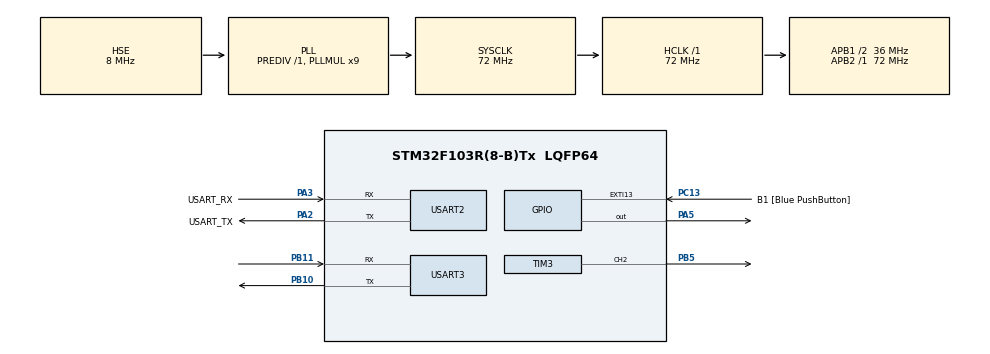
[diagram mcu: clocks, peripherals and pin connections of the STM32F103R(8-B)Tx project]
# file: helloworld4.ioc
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Mcu.Family=STM32F1
Mcu.Name=STM32F103R(8-B)Tx
Mcu.Package=LQFP64
NVIC.EXTI15_10_IRQn=true\:0\:0\:false\:false\:true\:true\:true\:true
NVIC.PriorityGroup=NVIC_PRIORITYGROUP_4
PA13.GPIO_Label=TMS
PA13.Mode=Serial_Wire
PA13.Signal=SYS_JTMS-SWDIO
PA14.GPIO_Label=TCK
PA14.Mode=Serial_Wire
PA14.Signal=SYS_JTCK-SWCLK
PA2.GPIO_Label=USART_TX
PA2.GPIO_Mode=GPIO_MODE_AF_PP
PA2.GPIO_PuPd=GPIO_NOPULL
PA2.GPIO_Speed=GPIO_SPEED_FREQ_LOW
PA2.Mode=Asynchronous
PA2.Signal=USART2_TX
PA3.GPIO_Label=USART_RX
PA3.GPIO_Mode=GPIO_MODE_AF_PP
PA3.GPIO_PuPd=GPIO_NOPULL
PA3.GPIO_Speed=GPIO_SPEED_FREQ_LOW
PA3.Mode=Asynchronous
PA3.Signal=USART2_RX
PA5.Signal=GPIO_Output
PB10.Mode=Asynchronous
PB10.Signal=USART3_TX
PB11.Mode=Asynchronous
PB11.Signal=USART3_RX
PB3.GPIO_Label=SWO
PB3.Signal=SYS_JTDO-TRACESWO
PB5.Signal=S_TIM3_CH2
PC13-TAMPER-RTC.GPIO_Label=B1 [Blue PushButton]
PC13-TAMPER-RTC.GPIO_PuPd=GPIO_NOPULL
PC13-TAMPER-RTC.Signal=GPXTI13
PC14-OSC32_IN.Mode=LSE-External-Oscillator
PC14-OSC32_IN.Signal=RCC_OSC32_IN
PC15-OSC32_OUT.Mode=LSE-External-Oscillator
PC15-OSC32_OUT.Signal=RCC_OSC32_OUT
PD0-OSC_IN.Mode=HSE-External-Clock-Source
PD0-OSC_IN.Signal=RCC_OSC_IN
PD1-OSC_OUT.Mode=HSE-External-Clock-Source
PD1-OSC_OUT.Signal=RCC_OSC_OUT
ProjectManager.HeapSize=0x200
ProjectManager.StackSize=0x400
ProjectManager.TargetToolchain=STM32CubeIDE
RCC.AHBFreq_Value=72000000
RCC.APB1CLKDivider=RCC_HCLK_DIV2
RCC.APB1Freq_Value=36000000
RCC.APB1TimFreq_Value=72000000
RCC.APB2Freq_Value=72000000
RCC.APB2TimFreq_Value=72000000
RCC.HCLKFreq_Value=72000000
RCC.PLLMUL=RCC_PLL_MUL9
RCC.PLLSourceVirtual=RCC_PLLSOURCE_HSE
RCC.RTCClockSelection=RCC_RTCCLKSOURCE_LSE
RCC.SYSCLKFreq_VALUE=72000000
RCC.SYSCLKSource=RCC_SYSCLKSOURCE_PLLCLK
RCC.USBFreq_Value=72000000
SH.S_TIM3_CH2.0=TIM3_CH2,PWM Generation2 CH2
TIM3.Channel-PWM\ Generation2\ CH2=TIM_CHANNEL_2
TIM3.Period=19999
TIM3.Prescaler=72
USART2.VirtualMode=VM_ASYNC
USART3.VirtualMode=VM_ASYNC
VP_TIM3_VS_ClockSourceINT.Mode=Internal
board=NUCLEO-F103RB

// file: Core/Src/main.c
/* USER CODE BEGIN Header */
/**
  ******************************************************************************
  * @file           : main.c
  * @brief          : Main program body
  ******************************************************************************
  * @attention
  *
  * Copyright (c) 2026 STMicroelectronics.
  * All rights reserved.
  *
  * This software is licensed under terms that can be found in the LICENSE file
  * in the root directory of this software component.
  * If no LICENSE file comes with this software, it is provided AS-IS.
  *
  ******************************************************************************
  */
/* USER CODE END Header */
#include "main.h"

TIM_HandleTypeDef htim3;

UART_HandleTypeDef huart2;
UART_HandleTypeDef huart3;

void SystemClock_Config(void);
static void MX_GPIO_Init(void);
static void MX_USART2_UART_Init(void);
static void MX_USART3_UART_Init(void);
static void MX_TIM3_Init(void);

int main(void)
{

  /* MCU Configuration--------------------------------------------------------*/

  /* Reset of all peripherals, Initializes the Flash interface and the Systick. */
  HAL_Init();

  /* Configure the system clock */
  SystemClock_Config();

  /* Initialize all configured peripherals */
  MX_GPIO_Init();
  MX_USART2_UART_Init();
  MX_USART3_UART_Init();
  MX_TIM3_Init();
  /* USER CODE BEGIN 2 */

//  int num = 0;
  //내가 입력할 문자열이 초과되지 않을만큼 넉넉하게 ~
  char text[100] = {0};
  char text2[100] = {0};
  /* USER CODE END 2 */

  /* Infinite loop */
  /* USER CODE BEGIN WHILE */
  while (1)
  {
	  //text라는 배열에 내가 지정한 문자열을 포멧을 이용해서 입력하겠다!
//	  sprintf(text,"num = %d",num);
//	  //1초간격으로 증가되는 null값을 C#에 전송한다
//	  HAL_UART_Transmit(&huart2, text, strlen(text), 100);
//	  num++;
//	  HAL_Delay(1000);

//	  //HAL_GetTick() : STM내부의 타이머 카운터값을 반환
//	  //STM32가 켜지면 0부터 출발해서 1밀리초당 1씩 증가
//	  sprintf(text, "GetTick = %d\n", HAL_GetTick());
//	  HAL_UART_Transmit(&huart2, text, strlen(text), 100);
//	  HAL_Delay(1000);

	  //example3 : C#이 보낸 고정길이의 데이터를 수신해라!
//	  if(HAL_UART_Receive(&huart2, text, 5, 500) == HAL_OK) {
//		  //송신용 text2 데이터 만들기
////		  sprintf(text2,"stm32 = %s\n",text);
////		  HAL_UART_Transmit(&huart2, text2, strlen(text2), 100);
//
//		  //현재 수신데이터는 text에 있는 상태이다.
//		  if(strcmp(text, "12345") == 0) {
//			  //일치
//			  HAL_UART_Transmit(&huart2, "LED_ON!\n", 8, 100);
//			  //PA5에 연결된 LED를 ON한다.
//			  HAL_GPIO_WritePin(GPIOA,GPIO_PIN_5, 1);
//		  } else if (strcmp(text, "67890") == 0) {
//			  //일치
//			  HAL_UART_Transmit(&huart2, "LED_OFF!\n", 9, 100);
//		  	  HAL_GPIO_WritePin(GPIOA,GPIO_PIN_5, 0);
//		  }
//	  }

	  //example4 C#이 길이가 가변적인 데이터를 보내는데 종료문자는 \n이다!
	  //C#에서 송신한 데이터가 있다면 1개씩 읽어서 수신버퍼에 카피한다
	  //그리고 종료문자가 감지되면 입력도니 문자열 한세트를 반환한다
//	  char recv = 0;
//	  int pos = 0;
//	  while(HAL_UART_Receive(&huart2, &recv, 1, 500) == HAL_OK) {
//		  text[pos] = recv;
//		  pos++;
//
//		  if(recv == '\n') {
//			 //종료조건
//			 text[pos] = '\0'; //널문자
//			 sprintf(text2,"stm32 = %s",text);
//			 HAL_UART_Transmit(&huart2, text2, strlen(text2), 100);
//
//			 //led on 수신시 PA5 ON
//			 //led off 수신시 PA5 OFF
//			 if(strcmp(text, "led on\n") == 0) {
//				 HAL_GPIO_WritePin(GPIOA,GPIO_PIN_5, 1);
//			 } else if(strcmp(text, "led off\n") == 0) {
//				 HAL_GPIO_WritePin(GPIOA,GPIO_PIN_5, 0);
//			 }
//			 break;
//		  }
//	  }

	  //example5 5초 간격으로 STM32가 C#쪽으로 hello world! 출력한다
	  HAL_UART_Transmit(&huart2, "Hello World!\n", 13, 100);
	  //STM32 메인루프는 HAL_Delay를 만나면 몯ㄴ 기능이 중지된다.
	  HAL_Delay(5000);
	  //버튼을 누르면 LED가 토글되도록 하려면 어떻게 해야겠는가?
	  //GPIO EXTI(외부 인터럽트)

    /* USER CODE END WHILE */

  }
}

void SystemClock_Config(void)
{
  RCC_OscInitTypeDef RCC_OscInitStruct = {0};
  RCC_ClkInitTypeDef RCC_ClkInitStruct = {0};

  /** Initializes the RCC Oscillators according to the specified parameters
  * in the RCC_OscInitTypeDef structure.
  */
  RCC_OscInitStruct.OscillatorType = RCC_OSCILLATORTYPE_HSE;
  RCC_OscInitStruct.HSEState = RCC_HSE_BYPASS;
  RCC_OscInitStruct.HSEPredivValue = RCC_HSE_PREDIV_DIV1;
  RCC_OscInitStruct.HSIState = RCC_HSI_ON;
  RCC_OscInitStruct.PLL.PLLState = RCC_PLL_ON;
  RCC_OscInitStruct.PLL.PLLSource = RCC_PLLSOURCE_HSE;
  RCC_OscInitStruct.PLL.PLLMUL = RCC_PLL_MUL9;
  if (HAL_RCC_OscConfig(&RCC_OscInitStruct) != HAL_OK)
  {
    Error_Handler();
  }

  /** Initializes the CPU, AHB and APB buses clocks
  */
  RCC_ClkInitStruct.ClockType = RCC_CLOCKTYPE_HCLK|RCC_CLOCKTYPE_SYSCLK
                              |RCC_CLOCKTYPE_PCLK1|RCC_CLOCKTYPE_PCLK2;
  RCC_ClkInitStruct.SYSCLKSource = RCC_SYSCLKSOURCE_PLLCLK;
  RCC_ClkInitStruct.AHBCLKDivider = RCC_SYSCLK_DIV1;
  RCC_ClkInitStruct.APB1CLKDivider = RCC_HCLK_DIV2;
  RCC_ClkInitStruct.APB2CLKDivider = RCC_HCLK_DIV1;

  if (HAL_RCC_ClockConfig(&RCC_ClkInitStruct, FLASH_LATENCY_2) != HAL_OK)
  {
    Error_Handler();
  }
}

static void MX_TIM3_Init(void)
{

  TIM_ClockConfigTypeDef sClockSourceConfig = {0};
  TIM_MasterConfigTypeDef sMasterConfig = {0};
  TIM_OC_InitTypeDef sConfigOC = {0};

  htim3.Instance = TIM3;
  htim3.Init.Prescaler = 72;
  htim3.Init.CounterMode = TIM_COUNTERMODE_UP;
  htim3.Init.Period = 19999;
  htim3.Init.ClockDivision = TIM_CLOCKDIVISION_DIV1;
  htim3.Init.AutoReloadPreload = TIM_AUTORELOAD_PRELOAD_DISABLE;
  if (HAL_TIM_Base_Init(&htim3) != HAL_OK)
  {
    Error_Handler();
  }
  sClockSourceConfig.ClockSource = TIM_CLOCKSOURCE_INTERNAL;
  if (HAL_TIM_ConfigClockSource(&htim3, &sClockSourceConfig) != HAL_OK)
  {
    Error_Handler();
  }
  if (HAL_TIM_PWM_Init(&htim3) != HAL_OK)
  {
    Error_Handler();
  }
  sMasterConfig.MasterOutputTrigger = TIM_TRGO_RESET;
  sMasterConfig.MasterSlaveMode = TIM_MASTERSLAVEMODE_DISABLE;
  if (HAL_TIMEx_MasterConfigSynchronization(&htim3, &sMasterConfig) != HAL_OK)
  {
    Error_Handler();
  }
  sConfigOC.OCMode = TIM_OCMODE_PWM1;
  sConfigOC.Pulse = 0;
  sConfigOC.OCPolarity = TIM_OCPOLARITY_HIGH;
  sConfigOC.OCFastMode = TIM_OCFAST_DISABLE;
  if (HAL_TIM_PWM_ConfigChannel(&htim3, &sConfigOC, TIM_CHANNEL_2) != HAL_OK)
  {
    Error_Handler();
  }
  HAL_TIM_MspPostInit(&htim3);

}

static void MX_USART2_UART_Init(void)
{

  huart2.Instance = USART2;
  huart2.Init.BaudRate = 115200;
  huart2.Init.WordLength = UART_WORDLENGTH_8B;
  huart2.Init.StopBits = UART_STOPBITS_1;
  huart2.Init.Parity = UART_PARITY_NONE;
  huart2.Init.Mode = UART_MODE_TX_RX;
  huart2.Init.HwFlowCtl = UART_HWCONTROL_NONE;
  huart2.Init.OverSampling = UART_OVERSAMPLING_16;
  if (HAL_UART_Init(&huart2) != HAL_OK)
  {
    Error_Handler();
  }

}

static void MX_USART3_UART_Init(void)
{

  huart3.Instance = USART3;
  huart3.Init.BaudRate = 115200;
  huart3.Init.WordLength = UART_WORDLENGTH_8B;
  huart3.Init.StopBits = UART_STOPBITS_1;
  huart3.Init.Parity = UART_PARITY_NONE;
  huart3.Init.Mode = UART_MODE_TX_RX;
  huart3.Init.HwFlowCtl = UART_HWCONTROL_NONE;
  huart3.Init.OverSampling = UART_OVERSAMPLING_16;
  if (HAL_UART_Init(&huart3) != HAL_OK)
  {
    Error_Handler();
  }

}

static void MX_GPIO_Init(void)
{
  GPIO_InitTypeDef GPIO_InitStruct = {0};

  /* GPIO Ports Clock Enable */
  __HAL_RCC_GPIOC_CLK_ENABLE();
  __HAL_RCC_GPIOD_CLK_ENABLE();
  __HAL_RCC_GPIOA_CLK_ENABLE();
  __HAL_RCC_GPIOB_CLK_ENABLE();

  /*Configure GPIO pin Output Level */
  HAL_GPIO_WritePin(GPIOA, GPIO_PIN_5, GPIO_PIN_RESET);

  /*Configure GPIO pin : B1_Pin */
  GPIO_InitStruct.Pin = B1_Pin;
  GPIO_InitStruct.Mode = GPIO_MODE_IT_RISING;
  GPIO_InitStruct.Pull = GPIO_NOPULL;
  HAL_GPIO_Init(B1_GPIO_Port, &GPIO_InitStruct);

  /*Configure GPIO pin : PA5 */
  GPIO_InitStruct.Pin = GPIO_PIN_5;
  GPIO_InitStruct.Mode = GPIO_MODE_OUTPUT_PP;
  GPIO_InitStruct.Pull = GPIO_NOPULL;
  GPIO_InitStruct.Speed = GPIO_SPEED_FREQ_LOW;
  HAL_GPIO_Init(GPIOA, &GPIO_InitStruct);

  /* EXTI interrupt init*/
  HAL_NVIC_SetPriority(EXTI15_10_IRQn, 0, 0);
  HAL_NVIC_EnableIRQ(EXTI15_10_IRQn);

}

void Error_Handler(void)
{
  __disable_irq();
  while (1)
  {
  }
}
